# psc3 register map
Vendor: Infineon Technologies; Series: PSC3; File version: 1.0
CPU: CM33 r0p1, little endian, MPU, FPU, VTOR, 3 interrupt priority bits
Registers are 32-bit, read-write, reset 0x0 unless marked. A register's access mark holds for its fields unless they carry their own. Offsets are from the block's base; [hi:lo] are bit positions; lines under a group give offsets from that group; {n}, {i} and the like mark numbered series; <NAME> marks a mode.

## HPPASS (part 1 of 2) — Top Level of MCPASS IP
Base 0x42B00000
0x70000 SARADC group — SAR ADC Core (Calibration and Test) NOTE: IP must be ENABLED to write and read these registers. When the block is disabled these registers are reset
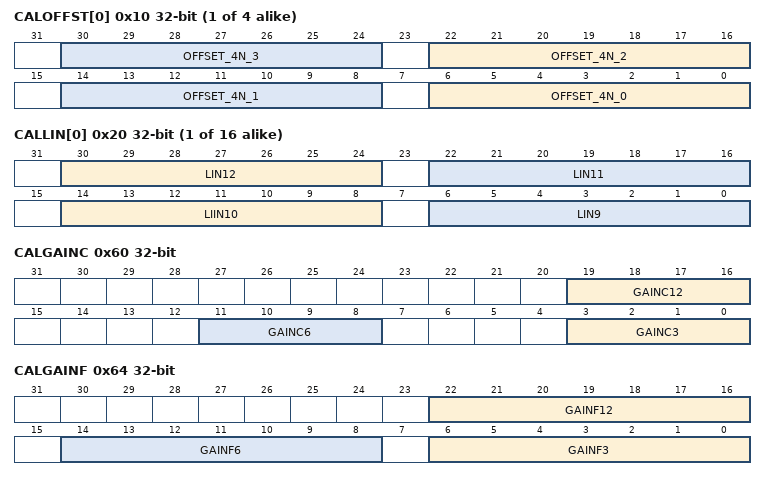
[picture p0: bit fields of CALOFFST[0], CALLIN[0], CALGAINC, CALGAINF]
  {0x10+4j} CALOFFST[{j}] (j=0..3) — SARADC Offset Calibration Values
    [8n+6:8n] OFFSET_4N_{n} (n=0..3) — 7-bit signed offset calibration value for sampler 4n + {n}
  {0x20+4j} CALLIN[{j}] (j=0..15) — SARADC Linearity Calibration Values
    [30:24] LIN12 — 7 bit signed linearity calibration value for bit 12 of this sampler
    [22:16] LIN11 — 7 bit signed linearity calibration value for bit 11 of this sampler
    [14:8] LIIN10 — 7 bit signed linearity calibration value for bit 10 of this sampler
    [6:0] LIN9 — 7 bit signed linearity calibration value for bit 9 of this sampler
  0x60 CALGAINC — SARADC Coarse-grained Gain Calibration Values
    [19:16] GAINC12 — Coarse-grained gain calibration value for gain=12 setting see description of GAINC3
    [11:8] GAINC6 — Coarse-grained gain calibration value for gain=6 setting see description of GAINC3
    [3:0] GAINC3 — Coarse-grained gain calibration value for gain=3 setting bit 3: SIGN, bits <2:0> : VALUE 0xF => -7: Voltage correction -14mV 0xE => -6: Voltage correction -12mV 0xD => -5: Voltage correction -10mV 0xC => -4: Voltage correction -8mV 0xB => -3: Voltage correction -6mV 0xA => -2: Voltage correction -4mV 0x9 => -1: Voltage correction -2mV 0x8 == 0x0 => 0: Voltage correction 0mV 0x1 => 1: Voltage correction +2mV 0x2 => 2: Voltage correction +4mV 0x3 => 3: Voltage correction +6mV 0x4 => 4: Voltage correction +8mV 0x5 => 5: Voltage correction +10mV 0x6 => 6: Voltage correction +12mV 0x7 => 7: Voltage correction +14mV
  0x64 CALGAINF — SARADC Fine-grained Gain Calibration Values
    [22:16] GAINF12 — 7-bit signed fine-grained gain calibration value for gain=12 setting
    [14:8] GAINF6 — 7-bit signed fine-grained gain calibration value for gain=6 setting
    [6:0] GAINF3 — 7-bit signed fine-grained gain calibration value for gain=3 setting
0x80000 SAR group — SAR ADC Controller
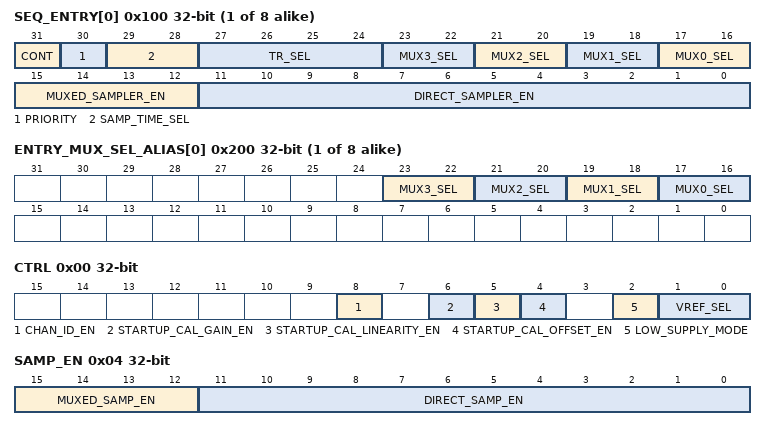
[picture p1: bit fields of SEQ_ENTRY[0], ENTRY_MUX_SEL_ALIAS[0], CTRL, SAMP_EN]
  {0x100+4j} SEQ_ENTRY[{j}] (j=0..7) — SAR Sequencer Table Entries
    [31] CONT — This bit enables continuous conversion for this entry. When this bit is set, this entry will trigger immediately when the SAR is ENABLED, and will be automatically re-triggered when this ENTRY has been completed. NOTE: Due to this automatic triggering, the TR_SEL field must be set to DISABLED for this ENTRY A continuous Entry should have sample time (SAMP_TIME_SEL is not DISABLED), otherwise this Entry will be continously triggered and use the majority of the SAR performance bandwidth. In other words, sample time is the only way to set the periodicity of a continous Entry.
    [30] PRIORITY — This bit selects the priority for this entry. High Priority samplers ready for conversion witll be processed before Low Priority samplers. 0: Low Priority 1: High Priority If the application configures a combination of High and Low Priority Entries, depending on the usage demand on the SAR from High Priority Entries, a Low Priority Entry might stay in HOLD state beyond a spec limit (See SAR_CFG.HOLD_VIOLATION and SAR_CFG.HOLD_CNT for more details). To ensure that the Low priority Entry did not stay in HOLD state beyond this limit, before reading a Low Priority Entry result, check the SAR_CFG.HOLD_VIOLATION status to ensure that the result is within spec.
    [29:28] SAMP_TIME_SEL — Sample Time Select. By default there is no additional sample time after the trigger (samplers are transitioned to HOLD state immediately on a trigger event) or select 1 of 3 available Sample Times in SAR_CFG.SAMPLE_TIME registers
      0=DISBALED (N/A); 1=SAMPLE_TIME_SEL0 (N/A); 2=SAMPLE_TIME_SEL1 (N/A); 3=SAMPLE_TIME_SEL2 (N/A)
    [27:24] TR_SEL — Trigger select for this Entry. By default disabled, or select 1 of 8 hardware triggers or AC trigger. Normally MCPASS internal triggers are PULSE triggers (see INFRA/TR_HW_MODE), however, a LEVEL trigger may also be used, but the trigger event is always on the positive edge of a LEVEL trigger. Once this ENTRY is triggered, the user must wait for SAR_ENTRY_DONE status to trigger this entry again. Otherwise a trigger collision status will be set for this ENTRY (see SAR_CFG.SAR_TR_COLLISION and MCPASS_MMIO.MCPASS_INTR)
      0=DISABLED (N/A); {v}=TR{v-1} (N/A) (v=1..8); 9=AC (N/A)
    [2n+17:2n+16] MUX{n}_SEL (n=0..3) — These bits control the input mux selection for sampler {n+12}
    [15:12] MUXED_SAMPLER_EN — These bits enable the 4 muxed samplers in this Entry. When this Entry is triggered any samplers with a bit set to '1' will be simultaneously sampled, held, and then converted. The mux setting for these samplers is determined by the following MUX(i)_SEL fields. Each one of these samplers maps to 4 result channels as determined by the mux setting 0,1,2, or 3 in order. The mapping is: MUXED_SAMPLER_EN - bit 12 (sampler 12) CHAN RESULTS are found in SAR_CFG.CHAN_RESULT12,13,14,15 MUXED_SAMPLER_EN - bit 13 (sampler 13) CHAN RESULTS are found in SAR_CFG.CHAN_RESULT16,17,18,19 MUXED_SAMPLER_EN - bit 14 (sampler 14) CHAN RESULTS are found in SAR_CFG.CHAN_RESULT20,21,22,23 MUXED_SAMPLER_EN - bit 15 (sampler 15) CHAN RESULTS are found in SAR_CFG.CHAN_RESULT24,25,26,27 Muxed samplers may also be specified as pseudo differential sampler pairs, but as described in SAR_CFG.CHAN_CFG.DIFF_EN, there are four possible inputs to each sampler in the even odd sampler pairs 12/13 or 14/15. Set DIFF_EN for the positive input (also configure post processing and storage specification) and also set MUX(even)_SEL to match this positive selection. To select the negative input, set the correspoing MUX(odd)_SEL. The odd bits of this field are ignored when the even sampler is enabled for PD.
    [11:0] DIRECT_SAMPLER_EN — These bits enable the 12 direct samplers in this Entry. When this Entry is triggered, any samplers with a bit set to '1' will be simultaneously sampled, held, and then converted. There is a 1-1 correspondence between these 12 samplers and the first 12 result channels. Therefore SAR results may be found in SAR_CFG.CHAN_RESULT0 - CHAN_RESULT12 When pseudo differential or PD is enabled in an even channel (SAR_CFG.CHAN_CFG.DIFF_EN) that sampler/channel it is the positive input of the PD pair, and the corresponding odd channel becomes the negative input. The result is processed and stored as specified in the even channel (e.g. AVG, FIR, RESULT REG,FIFO)
  {0x200+4j} ENTRY_MUX_SEL_ALIAS[{j}] (j=0..7) — SAR Sequencer MUX select alias registers
    [23:22] MUX3_SEL — Update SEQ_ENTRY.MUX3_SEL field
    [21:20] MUX2_SEL — Update SEQ_ENTRY.MUX2_SEL field
    [19:18] MUX1_SEL — Update SEQ_ENTRY.MUX1_SEL field
    [17:16] MUX0_SEL — Update SEQ_ENTRY.MUX0_SEL field Using this alias register, the user can read/write directly to the associated routing select fields in a given entry, without the need to do a read-modify-write operation on a SEQ_ENTRY register
  0x400 CFG group — SAR configuration and result registers
    0x00 CTRL — Control register
      [8] CHAN_ID_EN — FIFO Channel Number Identifier Enable
        0=DISABLED (When the FIFO is selected for a channel or FIR result (optional), 16-bit result data is stored in FIFO without tagging in the following format <00000>, <16-bit result>); 1=ENABLED (Result data is stored in FIFO is tagged with channel number identifier and stored as follows <5-bit chan_num>, <16-bit result>, where the 5-bit chan_num is 0-27 for channel results, and 30, 31 for FIR results)
      [6] STARTUP_CAL_GAIN_EN — Calibrate Gain on SAR Enable
        0=DISABLED (N/A); 1=ENABLED (N/A)
      [5] STARTUP_CAL_LINEARITY_EN — Calibration Linearity on SAR Enable
        0=DISABLED (N/A); 1=ENABLED (N/A)
      [4] STARTUP_CAL_OFFSET_EN — Calibration Offset on SAR Enable All selected CAL routines (OFFSET, LINEARITY, GAIN) in this register are run if these bits are set when the AC enables the SAR. The user must wait for BLOCK_READY (polling or interrupt) at which time SAR CAL and initialization is complete, before starting the application.
        0=DISABLED (N/A); 1=ENABLED (N/A)
      [2] LOW_SUPPLY_MODE — Low Supply Mode control - set this bit if VDDA supply range < 2.7V
        0=DISABLED (Disabled, VDDA supply is >= 2.7V); 1=ENABLED (Enabled, VDDA supply is < 2.7V)
      [1:0] VREF_SEL — SARADC VREF selection.
        0=VDDA (N/A); 1=EXT_REF (N/A); 2=RSVD_2 (N/A); 3=RSVD_3 (N/A)
    0x04 SAMP_EN — Sampler static enable configuration register
      [15:12] MUXED_SAMP_EN — Static Enables for Muxed Samplers. Must be set if in use by application, otherwise it is OFF and must not be selected in any SAR Entry.
      [11:0] DIRECT_SAMP_EN — Static Enables for Direct Samplers. Must be set if in use by application, otherwise it is OFF and must not be selected in any SAR Entry. A given SAR Entry is considered invalid if 1) There are no Samplers enabled and 2) For the given set of enabled Samplers, they all must be powered ON with this static setting. If the Entry is invalid, no action will be taken in the SAR sequencer if this Entry is triggered.
    0x08 SAMP_GAIN — Sampler gain configuration register
      [31:0] SAMP_GAIN — Static Sampler Gain Configure this register BEFORE enabling the SAR, it must be static during SAR operation. 0 = GAIN of 1 (default) 1 = GAIN of 3 2 = GAIN of 6 3 = GAIN of 12 Two bits per sampler: Sampler0 gain in [1:0] Sampler1 gain in [3:2] Sampler2 gain in [5:4] ... Sampler14 gain in [29:28] Sampler15 gain in [31:30] NOTE: If Psuedo Differential (PD) mode is enabled for a given Channel (see CHAN_CFG.DIFFERENTIAL_EN), then the associated samplers in the pseudo differential operation must be configured manually in this register to have the same SAMP_GAIN. For example if CHAN_CFG0 is set for PD mode, the associated differential samplers 0 and 1 should be set to the same gain.
    {0x10+4k} SAMPLE_TIME[{k}] (k=0..2) reset 0x1F — Sample Time configuration register
      [9:0] SAMPLE_TIME — Sample time (aperture) in given by (SAMPLE_TIME+1) clock cycles of CLK_HF/2. The range is 0..1023, which results in: 1*CLK_HF/2 - 1024 * CLK_HF/2 cycles There are 3 sample time registers and each ENTRY (SEQ_ENTRY.SAMPLE_TIME_SEL) can select DISABLED if no sample time is needed (see below) or one of these 3 registers if sample time is needed. WHEN SAMPLE TIME IS NOT REQUIRED: If 0 sample time is selected in SEQ_ENTRY.SAMPLE_TIME_SEL, this means when the trigger for that ENTRY is asserted, all the channels in that ENTRY are transitioned to HOLD state immediately and are queued for conversion. This scenario works well for DIRECT CHANNELS, because each input has a dedicated sampler which is either sampling, holding for conversion. Therefore after a given trigger, if the subsequent trigger is spaced out is time greater than or equal to the time required for all ENTRY channels to convert, plus a minimum sample time, no additional sample time (as would be programmed in this register) will be needed. WHEN SAMPLE TIME IS REQUIRED In the case of MUXed samplers, sample time is normally required because the routing is switched to the configured selections (SEQ_TABLE.MUXn_SEL) on trigger assertion. In this case minimum sample time is required. In a special case, however, if the mux selection is fixed and not changing, then it is equivalent to a direct connection, and in that case additional sampling time may not be required.
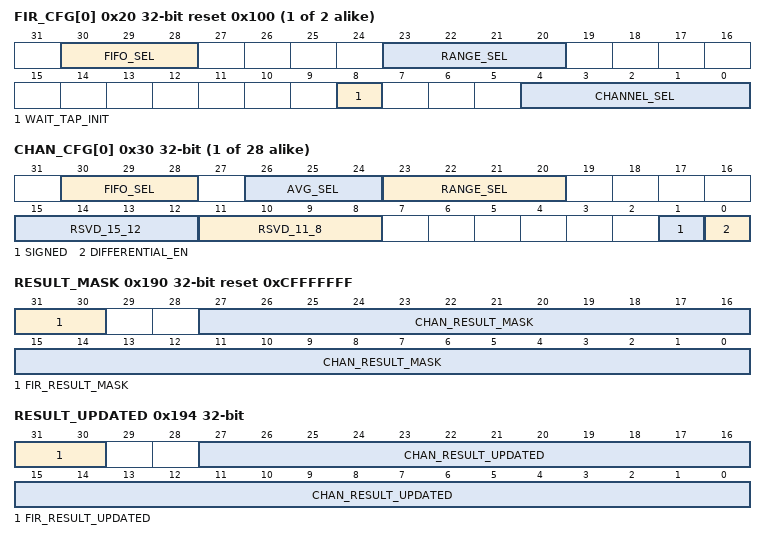
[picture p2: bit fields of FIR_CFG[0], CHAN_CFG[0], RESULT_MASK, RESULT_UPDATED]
    {0x20+4k} FIR_CFG[{k}] (k=0..1) reset 0x100 — FIR configuration register
      [30:28] FIFO_SEL — FIFO selections. Select 1 of the 4 for FIFOs for data storage There is a global setting for the number of FIFOs to be configured in LPPASS_MMIO/FIFO_CFG/CFG. If te indicated FIFO in this field is not configured, this setting will be ignored.
        0=DISABLED (N/A); {v}=FIFO_{v-1} (N/A) (v=1..4)
      [23:20] RANGE_SEL — Range detection. Select 1 of the 8 RANGE detection modules
        0=DISABLED (N/A); {v}=RANGE_{v-1} (N/A) (v=1..8)
      [8] WAIT_TAP_INIT — Wait for 16 samples before the first output is stored into a FIR_RESULT register or FIFO. This allows the user to ignore the FIR outputs until the FIR pipeline is initialized. .
        0=DISABLED (N/A); 1=ENABLED (N/A)
      [4:0] CHANNEL_SEL — Select which SAR channel will be the source for a given FIR input. When a new conversion output is available, the 16-tap FIR calculation is initiated (17 cycles for 16 taps), and a new FIR output is generated.
        0=DISABLED (N/A); {v}=CHANNEL_{v-1} (N/A) (v=1..28)
    {0x30+4k} CHAN_CFG[{k}] (k=0..27) — SAR Channel configuration register
      [30:28] FIFO_SEL — FIFO Select. Select 1 of the 4 for FIFO data storage. There is a global setting for the number of FIFOs to be configured in LPPASS_MMIO/FIFO_CFG/CFG. If te indicated FIFO in this field is not configured, this setting will be ignored.
        0=DISABLED (N/A); {v}=FIFO_{v-1} (N/A) (v=1..4)
      [26:24] AVG_SEL — Enable averaging for this channel. This implementation is accumulation only. There is no hardware shift option. For example, if AVG_2 is selected, the RESULT register (or FIFO) will contain a 13-bit result, for AVG_4 the RESULT register will contain a 14-bit result, etc.
        0=DISABLED (N/A); 1=AVG_2 (N/A); 2=AVG_4 (N/A); 3=AVG_8 (N/A); 4=AVG_16 (N/A); 5=RSVD_5 (N/A); 6=RSVD_6 (N/A); 7=RSVD_7 (N/A)
      [23:20] RANGE_SEL — Enable and select a RANGE resource for this channel
        0=DISABLED (N/A); {v}=RANGE_{v-1} (N/A) (v=1..8)
      [15:12] RSVD_15_12
      [11:8] RSVD_11_8
      [1] SIGNED — Signed Data Option
        0=UNSIGNED (Result data unsigned); 1=SIGNED (Result data is signed (sign extended if needed))
      [0] DIFFERENTIAL_EN — Differential Enable.
        0=DISABLED (Single Ended operation); 1=ENABLED (Pseudo Differential operation NOTE: Averaging (AVG_SEL below) is not available for this channel if Pseudo Differential is enabled. AVG_SEL must be set to the default DISABLED. POS and NEG inputs are simultaneously sampled, and then subtracted in hardware. Result is stored in the associated POS Channel RESULT reg Channels 0 - 11: There are 6 differential (even, odd) pairs. Example: Setting DIFFERENTIAL_EN in CHAN CFG 0 configures Sampler 0 as the POS input, and then Channel 1/Sampler 1 is automatically set as the NEG input. The result is stored in CHAN_RESULT 0. Channels 12 - 27: These are muxed channels which operate with 4 Samplers. so there are two differential pair groups Pair 1: CHAN 12-15, Sampler 12 (POS), CHAN 16-19, Sampler 13 (NEG) Pair 2: CHAN 20-23, Sampler 14 (POS), CHAN 24-27, Sampler 15 (NEG) Any channel of the even sampler could be PD-paired with any channel from the odd sampler Example: Setting DIFFERENTIAL_EN in CHAN_CFG 14, implies that Sampler 12 is the POS input where the SEQ_ENTRY.MUX0_SEL select must be set to 2 in the Entry configuration (see SEQ_ENTRY.MUXED_SAMPLER_EN for this mapping). Sampler 13 is automatically configured as the NEG input where input selection/routing is controlled by the SEQ_ENTRY.MUX1_SEL .The result is stored in CHAN_RESULT 14. This setting will be ignored for the NEG input channels 1,3,5,7,9,11, 16-19, 24-28)
    {0xB0+4k} RANGE_CFG[{k}] (k=0..7) — Range detect configuration register.
      [1:0] RANGE_COND — Range condition select.
        0=BELOW (result < RANGE_LOW); 1=INSIDE (RANGE_LOW <= result < RANGE_HIGH); 2=ABOVE (result > RANGE_HIGH); 3=OUTSIDE (result < RANGE_LOW || result >= RANGE_HIGH)
    {0xD0+4k} RANGE_LOW[{k}] (k=0..7) — Range detect low value register.
      [15:0] RANGE_LOW — Low threshold for range detect NOTE on unsigned/signed ADC RESULT RANGE (inclding averaging): If the channel that is selecting a given RANGE is declared as signed (CHAN_CFG.SIGNED), then the RANGE_HIGH and RANGE_LOW will be considered as signed 16-bit values, otherwise they will be considered as unsigned 16-bit values. FIR RESULT RANGE:The FIR output is considered as signed, therefore the RANGE_HIGH and RANGE_LOW for FIR comparison are always considered as signed 16-bit values.
    {0xF0+4k} RANGE_HIGH[{k}] (k=0..7) — Range detect high value register.
      [15:0] RANGE_HIGH — High threshold for range detect See RANGE_LOW for signed/unsigned usage rules
    {0x110+4k} CHAN_RESULT[{k}] (k=0..27) ro reset not defined — Channel result register
      [15:0] RESULT — SAR conversion working data of the channel. The data is written here if the corresponding bit if RESULT_MASK is set. (default is to write to CHAN_RESULT). The RESULT_MASK may be cleared if the channel data is targeted for the FIFO.
    {0x180+4k} FIR_RESULT[{k}] (k=0..1) ro reset not defined
      [15:0] RESULT — FIR output data. The data is written here if the corresponding bit in RESULT_MASK is set. (default is to write to FIR_RESULT) . The RESULT_MASK may be cleared if the FIR data is targeted for the FIFO.
    0x190 RESULT_MASK reset 0xCFFFFFFF — Channel result mask
      [31:30] FIR_RESULT_MASK — If set (default) the FIR_RESULT register will be used to store SAR conversion data for a given Entry and the associated ENTRY_DONE Interrupt will be generated. If this bit isn't set, the channel must be configured to store the result in a FIFO and the ENTRY_DONE Interrupt will not be generated.
      [27:0] CHAN_RESULT_MASK — If set (default) the CHAN_RESULT register will be used to store SAR conversion data for a given Entry and the associated ENTRY_DONE Interrupt will be generated. If this bit isn't set, the channel must be configured to store the result in a FIFO and the ENTRY_DONE Interrupt will not be generated.
    0x194 RESULT_UPDATED — Channel result register status
      [31:30] FIR_RESULT_UPDATED — Each bit will be set when the corresponding FIR_RESULT register is updated with a new result. Write 1 to clear.
      [27:0] CHAN_RESULT_UPDATED — Each bit will be set when the corresponding CHAN_RESULT register is updated with a new result. Write 1 to clear.
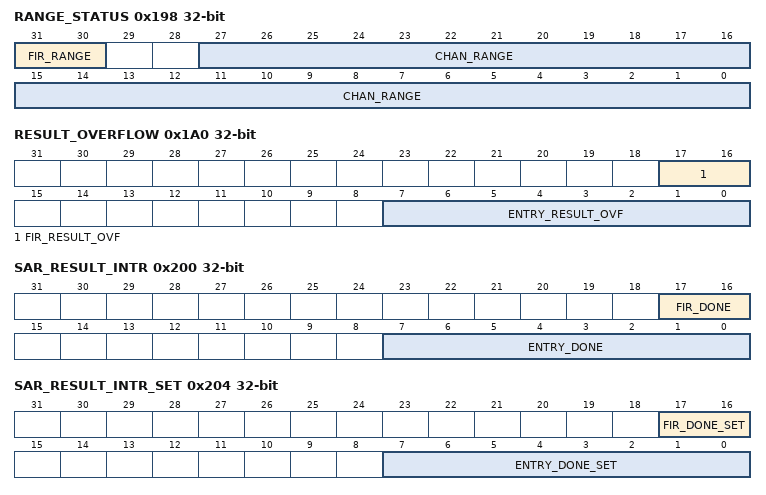
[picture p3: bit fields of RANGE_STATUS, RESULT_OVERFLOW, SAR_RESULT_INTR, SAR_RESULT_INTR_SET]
    0x198 RANGE_STATUS
      [31:30] FIR_RANGE — A given bit in this register will be set if the conversion result (after averaging) of that channel met the condition specified by the selected RANGE registers. Write with '1' to clear bit.
      [27:0] CHAN_RANGE — A given bit in this register will be set if the conversion result (after averaging) of that channel met the condition specified by the selected RANGE registers. Write with '1' to clear bit.
    0x19C SAR_STATUS ro
      [31] BUSY — If high then the SAR is busy with a conversion. This bit is always high when CONTINUOUS is set. Firmware should wait for this bit to be low before putting the SAR in power down.
    0x1A0 RESULT_OVERFLOW — Entry overflow status
      [17:16] FIR_RESULT_OVF — The associated bit is set in this register if the new FIR results are written before the associated SAR_RESULT_INTR/FIR_DONE bit has been cleared from the previous trigger.. This bit may be cleared by writing a '1' to the associated bit. Any bit set in this register will cause the MCPASS_INTR.RESULT_OVF bit to be set and this may be confgured to generate an interrupt (see MCPASS_MMIO).
      [7:0] ENTRY_RESULT_OVF — The associated bit is set in this register if the new Entry results are written before the associated SAR_RESULT_INTR/ENTRY_DONE bit has been cleared from the previous trigger. This bit may be cleared by writing a '1' to the associated bit. Any bit set in this register will cause the MCPASS_INTR.RESULT_OVF bit to be set and this may be confgured to generate an interrupt (see MCPASS_MMIO).
    0x1A4 ENTRY_TR_COLLISION — Entry trigger collision status
      [7:0] ENTRY_COL — The associated bit is set in this register if an Entry is triggered while processing for the previous trigger is still in progress, including sampling, conversion and post processing. Write a '1' to clear status in this register. Any bit set in this register will sety the MCPASS_INTR.ENTRY_TR_COLLISION to be set and this may be configured to generate an interrupt (see MCPASS_MMIO/MCPASS_INTR register).
    0x1A8 ENTRY_HOLD_VIOLATION — Entry hold violation status
      [7:0] HOLD_VIOL — The associated bit is set in this register if an Entry (and it's associated samplers) are in HOLD state greater than the ENTRY_HOLD_CNT value (see directly below), which indicates the associated channel results may not meet ADC accuracy specs. Write a '1' to clear status in this register. Any bit set in this register will sety the MCPASS_INTR.ENTRY_HOLD_VIOLATION to be set and this may be configured to generate an interrupt (see MCPASS_MMIO/MCPASS_INTR register).
    0x1AC ENTRY_HOLD_CNT reset 0x1D — Entry hold violation count
      [7:0] HOLD_CNT — This is the a global max HOLD count applied to all Entries. (See ENTRY_HOLD_VIOLATION above). The resolution of each count is 16 high frequency clock counts. For example, in PSOC C3 the high frequency clock is 160MHz, so each count will be 16/160MHz = 100ns. The default max HOLD time is 3us, thus the default value for this register is 29 (30 counts) NOTE: The violation can be asserted in the range of HOLD_CNT and HOLD_CNT+1
    0x200 SAR_RESULT_INTR — SAR Interrupt register
      [17:16] FIR_DONE — The associated FIR_DONE(N) status is set. The FIR_RESULT registers for the FIR modules are ready for reading
      [7:0] ENTRY_DONE — The associated ENTRY_DONE(N) status is set. The CHAN_RESULT registers for channels in this entry are ready for reading.
    0x204 SAR_RESULT_INTR_SET — SAR Interrupt request set register
      [17:16] FIR_DONE_SET — Write with '1' to set corresponding bit in interrupt request register. (a write of '0' has no effect).
      [7:0] ENTRY_DONE_SET — Write with '1' to set corresponding bit in interrupt request register. (a write of '0' has no effect).
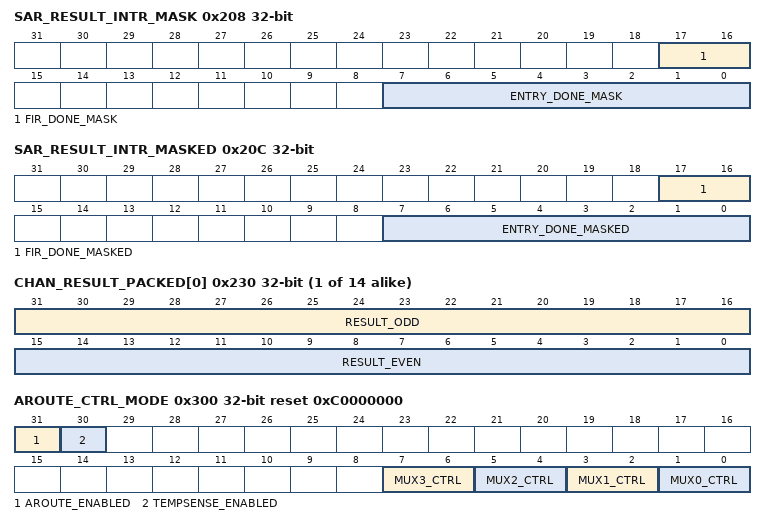
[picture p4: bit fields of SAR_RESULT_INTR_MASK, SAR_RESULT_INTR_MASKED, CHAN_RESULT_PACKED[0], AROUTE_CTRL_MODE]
    0x208 SAR_RESULT_INTR_MASK — SAR Interrupt request mask
      [17:16] FIR_DONE_MASK — Mask bit for corresponding bit in interrupt request register.
      [7:0] ENTRY_DONE_MASK — Mask bit for corresponding bit in interrupt request register.
    0x20C SAR_RESULT_INTR_MASKED ro — SAR Interrupt request masked
      [17:16] FIR_DONE_MASKED — Logical and of corresponding request and mask bits.
      [7:0] ENTRY_DONE_MASKED — Logical and of corresponding request and mask bits.
    0x210 SAR_RANGE_INTR — SAR Range Interrupt register
      [7:0] RANGE — The associated RANGE(N) status is set. The associated RANGE_STATUS is also set and available for reading.
    0x214 SAR_RANGE_INTR_SET — SAR Range Interrupt request set register
      [7:0] RANGE_SET — Write with '1' to set corresponding bit in interrupt request register.
    0x218 SAR_RANGE_INTR_MASK — SAR Range Interrupt request mask
      [7:0] RANGE_SET_MASK — Mask bit for corresponding bit in interrupt request register.
    0x21C SAR_RANGE_INTR_MASKED ro — SAR Range Interrupt request masked
      [7:0] RANGE_SET_MASKED — Logical and of corresponding request and mask bits.
    {0x230+4k} CHAN_RESULT_PACKED[{k}] (k=0..13) ro reset not defined — Channel result register packed with 2 results per register
      [31:16] RESULT_ODD — Odd numbered channel results. (e.g. 1, 3, 5, ... , 27)
      [15:0] RESULT_EVEN — Even numbered channel results (e.g. 0, 2, 4, ... , 26)
    0x300 AROUTE_CTRL_MODE reset 0xC0000000 — AROUTE control mode
      [31] AROUTE_ENABLED — Global AROUTE Enable 1: Enabled (default), controlled using selected MUXn_CTRL method 0: Disabled, all switches open, overrides all other switch controls.
      [30] TEMPSENSE_ENABLED — NOTE: This register field has been depricated and no longer in use. It may be left at the default value of '1' or it may be cleared to '0'.
      [7:6] MUX3_CTRL — The associated AROUTE MUX is controlled by the SAR sequencer or by FW, or AC
      [5:4] MUX2_CTRL — The associated AROUTE MUX is controlled by the SAR sequencer or by FW, or AC
      [3:2] MUX1_CTRL — The associated AROUTE MUX is controlled by the SAR sequencer or by FW, or AC
      [1:0] MUX0_CTRL — The associated AROUTE MUX is controlled by the SAR sequencer by static FW setting, or AC 0 (default) - Controlled by SAR sequencer using values in SEQ_ENTRY table MUXi_SEL fields or ENTRY_MUX_SEL_ALIAS register. This programming is explicit and easy to use and is intended for the majority of applications Setting 1 and 2 below are for advanced usage only. These settings override any SEQ_ENTRY setting. Therefore care must be taken to program SEQ_ENTRYs to NOT mix AROUTE_CTRL_MODE settings for the MUXes used in a given ENTRY. Also, for a given MUX using any of these below modes, only 1 ENTRY should specify the usage of that MUX. 1 - Controlled by FW using AROUTE_FW_SET and AROUTE_FW_CLR registers below. This mode must be used with care. Configuration is by individual switch control - buy only 1 switch may be set for each MUX, otherwise the routes will be shorted to each other. 2 - Controlled by AC using ACTRLR/TIMER_TABLE/TT_CFG3/SAR_AROUTE_TR and SAR_AROUTE_SEL fields. When this mode is used, the AC must be programmed to fully control that ENTRY. In that case, for example, the external trigger will be routed to the AC code that sets the MUX, triggers that ENTRY, waits for the ENTRY to be completed, switched the MUX to the next selection, triggers that ENTRY again, etc.
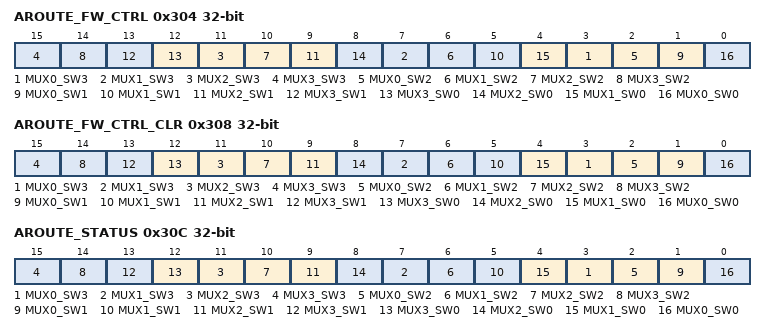
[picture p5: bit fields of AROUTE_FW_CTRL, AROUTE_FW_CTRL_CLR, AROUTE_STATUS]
    0x304 AROUTE_FW_CTRL — AROUTE firmware switch control set (individual)
      [4n+3] MUX{n}_SW3 (n=0..3)
      [4n+2] MUX{n}_SW2 (n=0..3)
      [4n+1] MUX{n}_SW1 (n=0..3)
      [12] MUX3_SW0
      [8] MUX2_SW0
      [4] MUX1_SW0
      [0] MUX0_SW0 — Firmware control: 0=open, 1=close switch. Write with '1' to set bit. To clear this bit write a '1' to the associated bit in AROUTE_FW_CLR register
    0x308 AROUTE_FW_CTRL_CLR — AROUTE firmware switch control clear (individual)
      [4n+3] MUX{n}_SW3 (n=0..3)
      [4n+2] MUX{n}_SW2 (n=0..3)
      [4n+1] MUX{n}_SW1 (n=0..3)
      [12] MUX3_SW0
      [8] MUX2_SW0
      [4] MUX1_SW0
      [0] MUX0_SW0 — Write '1' to clear corresponding bit in AROUTE_FW_CTRL. A read of this register returns the values of AROUTE_FW_CTRL.
    0x30C AROUTE_STATUS ro — AROUTE switch status
      [4n+3] MUX{n}_SW3 (n=0..3)
      [4n+2] MUX{n}_SW2 (n=0..3)
      [4n+1] MUX{n}_SW1 (n=0..3)
      [12] MUX3_SW0
      [8] MUX2_SW0
      [4] MUX1_SW0
      [0] MUX0_SW0 — Read back the current state of the associated switch control (regardless of mode)
    0x310 TEMPSENSE_CTRL — Temperture Sensor Control
      [0] TEMPSENSE_CURRENT_SEL — Used for Delta Vbe Temperature Sensor Algoritm (see BROS for full details) 0: BJT current is 1uA (default) 1: Add 8uA to BJT current
  {0x800+0x80*j} FIR[{j}] (j=0..1) group — SAR FIR coefficient and tap registers
    {0x0+4k} FIR_COEFS[{k}] (k=0..15) — FIR Coeffecients
      [15:0] COEF — FIR Coefficient Value The coefficient values can range from -1+1/215 to 1-1/215 with a resolution of 1/215. The coefficient uses twos-complement notation and the decimal point is fixed to the right of the most significant bit. Examples: -0.25 = 0xE000 and 0.25 = 0x2000 NOTE: The max absolute value of the FIR gain must be less than 8 (sum of the coeffients), otherwise the result may overflow the allocated 16-bits.
    {0x40+4k} FIR_TAPS[{k}] (k=0..15)
      [15:0] TAP — FIR Tap Value In normal operation R/W by hardware Only when MCPASS IP is enabled and SAR is enabled - these registers may be written to and read by software, typically for debug puposes.
